# YTM32B1HA0 register map
Vendor: YTMicro; File version: 1.0
CPU: little endian, MPU, FPU, 2 interrupt priority bits
Registers are 32-bit, read-write, reset 0x0 unless marked. A register's access mark holds for its fields unless they carry their own. Offsets are from the block's base; [hi:lo] are bit positions; {n}, {i} and the like mark numbered series; 'fields as' and 'values as' point back to an identical list.

## ENET (part 10 of 10) — Ethernet Quality-of-Service
Base 0x401E4000; register names take the prefix ENET_
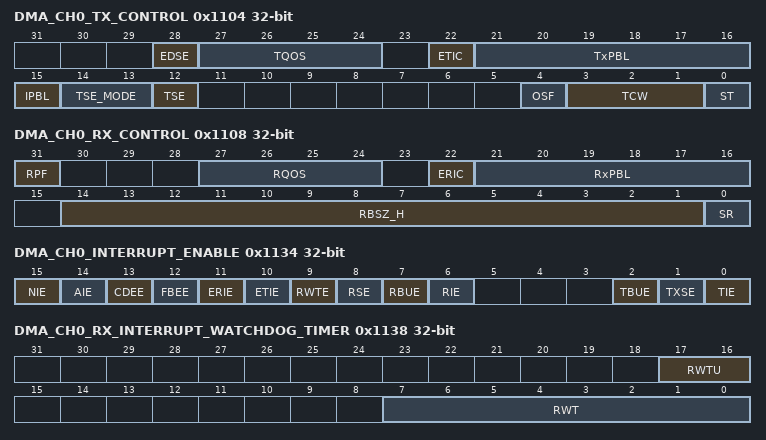
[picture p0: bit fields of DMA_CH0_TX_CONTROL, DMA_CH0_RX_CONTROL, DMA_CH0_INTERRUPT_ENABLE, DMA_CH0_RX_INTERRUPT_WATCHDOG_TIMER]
0x1104 DMA_CH0_TX_CONTROL — The DMA Channel n Transmit Control register controls the Tx features such as PBL, TCP segmentation, and Tx Channel weights.
  [28] EDSE — When this bit is set, the corresponding channel uses Enhanced Descriptors that are 32 Bytes for both Normal and Context Descriptors. When reset, the corresponding channel uses the descriptors that are 16 Bytes.
    0=Enhanced Descriptor is disabled; 1=Enhanced Descriptor is disabled
  [27:24] TQOS — This field is used to drive arqos_m_o[3:0] or awqos_m_o[3:0] output signals for all transactions of DMA Tx Channel n.
  [22] ETIC — When this bit is set, Early Transmit Interrupt (ETI) status is set after completion of transfer of data from buffers of a transmit descriptor in which IOC bit (TDES2[31]) is set. When this bit is reset, ETI is set only after a complete packet is transferred to the MTL TX FIFO memory.
    0=Early Transmit Interrupt is disabled; 1=Early Transmit Interrupt is enabled
  [21:16] TxPBL — These bits indicate the maximum number of beats to be transferred in one DMA block data transfer. The DMA always attempts max burst as specified in PBL each time it starts a burst transfer on the application bus. You can program PBL with any of the following values: 1, 2, 4, 8, 16, or 32. Any other value results in undefined behavior. To transfer more than 32 beats, perform the following steps: 1. Set the 8xPBL mode in DMA_CH0_Control register. 2. Set the TxPBL. Note: The maximum value of TxPBL must be less than or equal to half the Tx Queue size (TQS field of MTL_TxQ[n]_Operation_Mode register) in terms of beats. This is required so that the Tx Queue has space to store at least another Tx PBL worth of data while the MTL Tx Queue Controller is transferring data to MAC. For example, in 64-bit data width configurations the total locations in Tx Queue of size 512 bytes is 64, TxPBL and 8xPBL needs to be programmed to less than or equal to 32.
  [15] IPBL — When this bit is set, the DMA does not check for PBL number of locations in the MTL before initiating a transfer. If space is not available, the MTL may use handshaking to slow the DMA. Note: This bit/mode must not be used when multiple Transmit DMA Channels are enabled as it may block other Transmit and Receive DMA Channels from accessing the Read Data Channel of AXI bus until space is available in Transmit Queue for current transfer.
    0=Ignore PBL Requirement is disabled; 1=Ignore PBL Requirement is enabled
  [14:13] TSE_MODE
    0=TSO/USO (segmentation functionality is enabled). In this mode, the setting of TSE bit enables the TSO/USO segmentation.; 1=UFO with Checksum (UDP Fragmentation over IPv4 with Checksum). In this mode, the setting of TSE bit enables the UDP fragmentation functionality with Checksum for all the UDP packets.; 2=UFO without Checksum (UDP Fragmentation over IPv4 with Checksum). In this mode, the setting of TSE bit enables the UDP fragmentation functionality without Checksum for all the UDP packets.
  [12] TSE — When this bit is set, the DMA performs the TCP segmentation or UDP Segmentation/Fragmentation for packets in this channel. The TCP segmentation or UDP packet's segmentation/Fragmentation is done only for those packets for which the TSE bit (TDES0[19]) is set in the Tx Normal descriptor.When this bit is set, the TxPBL value must be greater than 4.
    0=TCP Segmentation is disabled; 1=TCP Segmentation is enabled
  [4] OSF — When this bit is set, it instructs the DMA to process the second packet of the Transmit data even before the status for the first packet is obtained.
    0=Operate on Second Packet disabled; 1=Operate on Second Packet enabled
  [3:1] TCW — This field indicates the weight assigned to the corresponding Transmit channel. When reset is complete, this field is set to 0 for all channels by default, resulting in equal weights to all channels.
  [0] ST — When this bit is set, transmission is placed in the Running state. The DMA checks the Transmit list at the current position for a packet to be transmitted. The DMA tries to acquire descriptor from either of the following positions: ■ The current position in the list This is the base address of the Transmit list set by the DMA_CH0_TxDesc_List_Address register. ■ The position at which the transmission was previously stopped If the DMA does not own the current descriptor, the transmission enters the Suspended state and the TBU bit of the DMA_CH0_Status register is set. The Start Transmission command is effective only when the transmission is stopped. If the command is issued before setting the DMA_CH0_TxDesc_List_Address register, the DMA behavior is unpredictable. When this bit is reset, the transmission process is placed in the Stopped state after completing the transmission of the current packet. The Next Descriptor position in the Transmit list is saved, and it becomes the current position when the transmission is restarted. To change the list address, you need to program DMA_CH0_TxDesc_List_Address register with a new value when this bit is reset. The new value is considered when this bit is set again. The stop transmission command is effective only when the transmission of the current packet is complete or the transmission is in the Suspended state.
    0=Stop Transmission Command; 1=Start Transmission Command
0x1108 DMA_CH0_RX_CONTROL — The DMA Channeli Receive Control register controls the Rx features such as PBL, buffer size, and extended status.
  [31] RPF — When this bit is set to 1, then DWC_ether_qos automatically flushes the packet from the Rx Queues destined to this DMA Rx Channel, when it is stopped. When this bit remains set and the DMA is re-started by the software driver, the packets residing in the Rx Queues that were received when this RxDMA was stopped, get flushed out. The packets that are received by the MAC after the RxDMA is re-started are routed to the RxDMA. The flushing happens on the Read side of the Rx Queue. When this bit is set to 0, the DWC_ether_qos not flush the packet in the Rx Queue destined to this RxDMA Channel when it is STOP state. This may in turn cause head-of-line blocking in the corresponding RxQueue.
    0=Rx Packet Flush is disabled; 1=Rx Packet Flush is enabled
  [27:24] RQOS — This field is used to drive arqos_m_o[3:0] or awqos_m_o[3:0] output signals for all transactions of DMA Rx Channel n.
  [22] ERIC — When this bit is set, Early Receive Interrupt (ERI) status is set after completion of every burst transfer of data from the Rx DMA to the buffer. When this bit is reset, ERI is set only after a complete buffer is filled up by the RxDMA.
    0=Early Receive Interrupt is disabled; 1=Early Receive Interrupt is disabled
  [21:16] RxPBL — These bits indicate the maximum number of beats to be transferred in one DMA block data transfer. The DMA always attempts max burst as specified in PBL each time it starts a burst transfer on the application bus. You can program PBL with any of the following values: 1, 2, 4, 8, 16, or 32. Any other value results in undefined behavior. To transfer more than 32 beats, perform the following steps: 1. Set the 8xPBL mode in the DMA_CH0_Control register. 2. Set the RxPBL. Note: The maximum value of RxPBL must be less than or equal to half the Rx Queue size (RQS field of MTL_RxQ[n]_Operation_Mode register) in terms of beats. This is required so that the Rx Queue has space to store at least another Rx PBL worth of data while the Rx DMA is transferring a block of data. For example, in 64-bit data width configurations the total locations in Rx Queue of size 512 bytes is 64, so RxPBL and 8xPBL needs to be programmed to less than or equal to 32.
  [14:1] RBSZ_H — RBSZ[13:0] is split into two fields higher RBSZ_13_y and lower RBSZ_x_0. The RBSZ[13:0] field indicates the size of the Rx buffers specified in bytes. The maximum buffer size is limited to 16K bytes. The buffer size is applicable to payload buffers when split headers are enabled. Note: The buffer size must be a multiple of 4, 8, or 16 depending on the data bus widths (32-bit, 64-bit, or 128-bit respectively). This is required even if the value of buffer address pointer is not aligned to data bus width. Hence the lower RBSZ_x_0 bits are read-only and the value is considered as all-zero. Thus the RBSZ_13_y indicates the buffer size in terms of locations (with the width same as bus-width).
  [0] SR — When this bit is set, the DMA tries to acquire the descriptor from the Receive list and processes the incoming packets. The DMA tries to acquire descriptor from either of the following positions: ■ The current position in the list This is the address set by the DMA_CH0_RxDesc_List_Address register. ■ The position at which the Rx process was previously stopped If the DMA does not own the current descriptor, the reception is suspended and the RBU bit of the DMA_CH0_Status register is set. The Start Receive command is effective only when the reception is stopped. If the command is issued before setting the DMA_CH0_RxDesc_List_Address register, the DMA behavior is unpredictable. When this bit is reset, the Rx DMA operation is stopped after the transfer of the current packet. The next descriptor position in the Receive list is saved, and it becomes the current position after the Rx process is restarted. The Stop Receive command is effective only when the Rx process is in the Running (waiting for Rx packet) or Suspended state.
    0=Stop Receive; 1=Start Receive
0x1110 DMA_CH0_TXDESC_LIST_HADDRESS — The Channeli Tx Descriptor List HAddress register has the higher 8 or 16 bits of the start address of the Transmit descriptor list. You can write to this register only when the Tx DMA has stopped, that is, the ST bit is set to zero in DMA_CHi_Tx_Control register. When stopped, this register can be written with a new descriptor list address. When you set the ST bit to 1, the DMA takes the newly-programmed descriptor base address. If this register is not changed when the ST bit is set to 0, the DMA takes the descriptor address where it was stopped earlier. This register must be programmed with desired the higher address before programming the DMA_CHi_TxDesc_List_Address register.
  [7:0] TDESHA — This field contains the most-significant 8 or 16 bits of the 40- or 48-bit base address of the first descriptor in the Transmit descriptor list.
0x1114 DMA_CH0_TXDESC_LIST_ADDRESS — The Channeli Tx Descriptor List Address register points the DMA to the start of Transmit descriptor list. The descriptor lists reside in the physical memory space of the application and must be Word, Dword, or Lword-aligned (for 32-bit, 64-bit, or 128-bit data bus). The DMA internally converts it to bus width aligned address by making the corresponding LSB to low. You can write to this register only when the Tx DMA has stopped, that is, the ST bit is set to zero in DMA_CH0_Tx_Control register. When stopped, this register can be written with a new descriptor list address. When you set the ST bit to 1, the DMA takes the newly-programmed descriptor base address. If this register is not changed when the ST bit is set to 0, the DMA takes the descriptor address where it was stopped earlier.
  [31:3] TDESLA — This field contains the base address of the first descriptor in the Transmit descriptor list. The DMA ignores the LSB bits (1:0, 2:0, or 3:0) for 32-bit, 64-bit, or 128-bit bus width and internally takes these bits as all-zero. Therefore, these LSB bits are read-only (RO). The width of this field depends on the configuration: ■ 31:2 for 32-bit configuration ■ 31:3 for 64-bit configuration ■ 31:4 for 128-bit configuration
0x1118 DMA_CH0_RXDESC_LIST_HADDRESS — The Channeli Rx Descriptor List HAddress register has the higher 8 or 16 bits of the start address of the Receive descriptor list. Writing to this register is permitted only when reception is stopped. When stopped, this register must be written to before the receive Start command is given. You can write to this register only when Rx DMA has stopped, that is, SR bit is set to zero in the DMA_CHi_RxDesc_List_Address register When you set the SR bit to 1, the DMA takes the newly programmed descriptor base address.
  [7:0] RDESHA — This field contains the most-significant 8 or 16 bits of the 40-bit or 48-bit base address of the first descriptor in the Rx Descriptor list.
0x111C DMA_CH0_RXDESC_LIST_ADDRESS — The Channeli Rx Descriptor List Address register points the DMA to the start of Receive descriptor list. This register points to the start of the Receive Descriptor List. The descriptor lists reside in the physical memory space of the application and must be Word, Dword, or Lword-aligned (for 32-bit, 64-bit, or 128-bit data bus). The DMA internally converts it to bus width aligned address by making the corre- sponding LS bits low. Writing to this register is permitted only when reception is stopped. When stopped, this register must be written to before the receive Start command is given. You can write to this register only when Rx DMA has stopped, that is, SR bit is set to zero in DMA_CH0_Rx_Control register. When stopped, this register can be written with a new descriptor list address. When you set the SR bit to 1, the DMA takes the newly programmed descriptor base address.
  [31:3] RDESLA — This field contains the base address of the first descriptor in the Receive descriptor list. The DMA ignores the LSB bits (1:0, 2:0, or 3:0) for 32-bit, 64-bit, or 128-bit bus width and internally takes these bits as all-zero. Therefore, these LSB bits are read-only (RO). The width of this field depends on the configuration: ■ 31:2 for 32-bit configuration ■ 31:3 for 64-bit configuration ■ 31:4 for 128-bit configuration
0x1120 DMA_CH0_TXDESC_TAIL_POINTER — The Channeli Tx Descriptor Tail Pointer register points to an offset from the base and indicates the location of the last valid descriptor.
  [31:3] TDTP — This field contains the tail pointer for the Tx descriptor ring. The software writes the tail pointer to add more descriptors to the Tx channel. The hardware tries to transmit all packets referenced by the descriptors between the head and the tail pointer registers. The width of this field depends on the configuration: ■ 31:2 for 32-bit configuration ■ 31:3 for 64-bit configuration ■ 31:4 for 128-bit configuration
0x1128 DMA_CH0_RXDESC_TAIL_POINTER — The Channel n Rx Descriptor Tail Pointer Points to an offset from the base and indicates the location of the last valid descriptor.
  [31:3] RDTP — This field contains the tail pointer for the Rx descriptor ring. The software writes the tail pointer to add more descriptors to the Rx channel. The hardware tries to receive all packets referenced by the descriptors between the head and the tail pointer registers. The width of this field depends on the configuration: ■ 31:2 for 32-bit configuration ■ 31:3 for 64-bit configuration ■ 31:4 for 128-bit configuration
0x112C DMA_CH0_TXDESC_RING_LENGTH — The Tx Descriptor Ring Length register contains the length of the Transmit descriptor ring.
  [9:0] TDRL — This field sets the maximum number of Tx descriptors in the circular descriptor ring. The maximum number of descriptors is limited to 1K descriptors. Synopsys recommends a minimum ring descriptor length of 4. For example, You can program any value up to 0x3FF in this field. This field is 10 bits wide, if you program 0x3FF, you can have 1024 descriptors. If you want to have 10 descriptors, program it to a value of 0x9.
0x1130 DMA_CH0_RXDESC_RING_LENGTH — The Channeli Rx Descriptor Ring Length register contains the length of the Receive descriptor circular ring.
  [9:0] RDRL — This field sets the maximum number of Rx descriptors in the circular descriptor ring. The maximum number of descriptors is limited to 1K descriptors. Synopsys recommends a minimum ring descriptor length of 4. For example, You can program any value up to 0x3FF in this field. This field is 10 bits wide, if you program 0x3FF, you can have 1024 descriptors. If you want to have 10 descriptors, program it to a value of 0x9.
0x1134 DMA_CH0_INTERRUPT_ENABLE — The Channel n Interrupt Enable register enables the interrupts reported by the Status register.
  [15] NIE — When this bit is set, the normal interrupt summary is enabled. This bit enables the following interrupts in the DMA_CH0_Status register: ■ Bit 0: Transmit Interrupt ■ Bit 2: Transmit Buffer Unavailable ■ Bit 6: Receive Interrupt ■ Bit 11: Early Receive Interrupt When this bit is reset, the normal interrupt summary is disabled.
    0=Normal Interrupt Summary is disabled; 1=Normal Interrupt Summary is enabled
  [14] AIE — When this bit is set, the abnormal interrupt summary is enabled. This bit enables the following interrupts in the DMA_CH0_Status register: ■ Bit 1: Transmit Process Stopped ■ Bit 7: Rx Buffer Unavailable ■ Bit 8: Receive Process Stopped ■ Bit 9: Receive Watchdog Timeout ■ Bit 10: Early Transmit Interrupt ■ Bit 12: Fatal Bus Error ■ Bit 13: Context Descriptor Error When this bit is reset, the abnormal interrupt summary is disabled.
    0=Abnormal Interrupt Summary is disabled; 1=Abnormal Interrupt Summary is enabled
  [13] CDEE — When this bit is set along with the AIE bit, the Descriptor error interrupt is enabled. When this bit is reset, the Descriptor error interrupt is disabled.
    0=Context Descriptor Error interrupt is disabled; 1=Context Descriptor Error interrupt is enabled
  [12] FBEE — When this bit is set along with the AIE bit, the Fatal Bus error interrupt is enabled. When this bit is reset, the Fatal Bus Error error interrupt is disabled.
    0=Fatal Bus Error interrupt is disabled; 1=Fatal Bus Error interrupt is enabled
  [11] ERIE — When this bit is set along with the NIE bit, the Early Receive interrupt is enabled. When this bit is reset, the Early Receive interrupt is disabled.
    0=Early Receive interrupt is disabled; 1=Early Receive interrupt is enabled
  [10] ETIE — When this bit is set along with the AIE bit, the Early Transmit interrupt is enabled. When this bit is reset, the Early Transmit interrupt is disabled.
    0=Early Transmit interrupt is disabled; 1=Early Transmit interrupt is enabled
  [9] RWTE — When this bit is set along with the AIE bit, the Receive Watchdog Timeout interrupt is enabled. When this bit is reset, the Receive Watchdog Timeout interrupt is disabled.
    0=Receive Watchdog Timeout interrupt is disabled; 1=Receive Watchdog Timeout interrupt is enabled
  [8] RSE — When this bit is set along with the AIE bit, the Receive Stopped interrupt is enabled. When this bit is reset, the Receive Stopped interrupt is disabled.
    0=Receive Stopped interrupt is disabled; 1=Receive Stopped interrupt is enabled
  [7] RBUE — When this bit is set along with the AIE bit, the Receive Buffer Unavailable interrupt is enabled. When this bit is reset, the Receive Buffer Unavailable interrupt is disabled.
    0=Receive Buffer Unavailable interrupt is disabled; 1=Receive Buffer Unavailable interrupt is enabled
  [6] RIE — When this bit is set along with the NIE bit, the Receive interrupt is enabled. When this bit is reset, the Receive interrupt is disabled.
    0=Receive interrupt is disabled; 1=Receive interrupt is enabled
  [2] TBUE — When this bit is set along with the NIE bit, the Transmit Buffer Unavailable interrupt is enabled. When this bit is reset, the Transmit Buffer Unavailable interrupt is disabled.
    0=Transmit Buffer Unavailable interrupt is disabled; 1=Transmit Buffer Unavailable interrupt is enabled
  [1] TXSE — When this bit is set along with the AIE bit, the Transmission Stopped interrupt is enabled. When this bit is reset, the Transmission Stopped interrupt is disabled.
    0=Transmit Stopped interrupt is disabled; 1=Transmit Stopped interrupt is enabled
  [0] TIE — When this bit is set along with the NIE bit, the Transmit interrupt is enabled. When this bit is reset, the Transmit interrupt is disabled.
    0=Transmit interrupt is disabled; 1=Transmit interrupt is enabled
0x1138 DMA_CH0_RX_INTERRUPT_WATCHDOG_TIMER — The Receive Interrupt Watchdog Timer register indicates the watchdog timeout for Receive Interrupt (RI) from the DMA. When this register is written with a non-zero value, it enables the watchdog timer for the RI bit of the DMA_CHn_Status register.
  [17:16] RWTU — This fields indicates the number of system clock cycles corresponding to one unit in RWT field. ■ 2'b00: 256 ■ 2'b01: 512 ■ 2'b10: 1024 ■ 2'b11: 2048 For example, when RWT=2 and RWTU=1, the watchdog timer is set for 2*512=1024 system clock cycles.
  [7:0] RWT — This field indicates the number of system clock cycles, multiplied by factor indicated in RWTU field, for which the watchdog timer is set. The watchdog timer is triggered with the programmed value after the Rx DMA completes the transfer of a packet for which the RI bit is not set in the DMA_CH(#i)_Status register, because of the setting of Interrupt Enable bit in the corresponding descriptor RDES3[30]. When the watchdog timer runs out, the RI bit is set and the timer is stopped. The watchdog timer is reset when the RI bit is set high because of automatic setting of RI as per the Interrupt Enable bit RDES3[30] of any received packet.
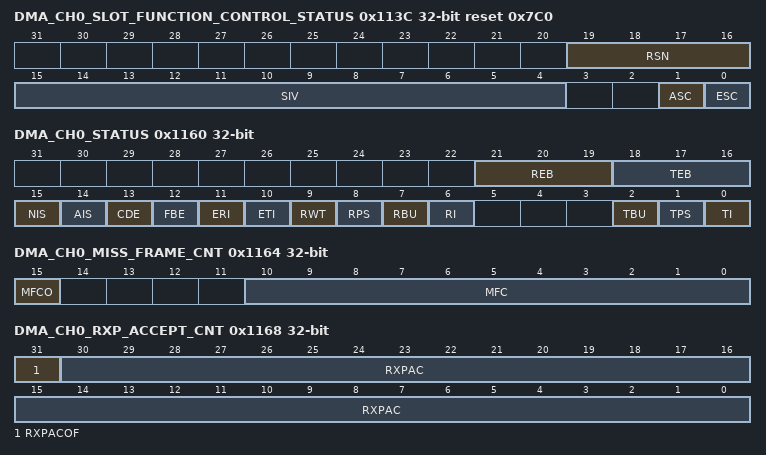
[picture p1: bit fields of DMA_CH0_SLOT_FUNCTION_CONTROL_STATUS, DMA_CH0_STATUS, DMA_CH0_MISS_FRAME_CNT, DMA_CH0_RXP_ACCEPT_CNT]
0x113C DMA_CH0_SLOT_FUNCTION_CONTROL_STATUS reset 0x7C0 — The Slot Function Control and Status register contains the control bits for slot function and the status for Transmit path.
  [19:16] RSN ro — This field gives the current value of the reference slot number in the DMA. It is used for slot comparison.
  [15:4] SIV — This field controls the period of the slot interval in which the TxDMA fetches the scheduled packets. A value of 0 specifies the slot interval of 1 us while the maximum value 4095 specifies the slot interval of 4096us. The default/reset value is 0x07C which corresponds to slot interval of 125us
  [1] ASC — When set, this bit enables the DMA to fetch the data from the buffer when the slot number (SLOTNUM) programmed in the Tx descriptor is ■ equal to the reference slot number given in the RSN field or ■ ahead of the reference slot number by up to two slots This bit is applicable only when the ESC bit is set. Values: ■ 0x0 (DISABLE): Advance Slot Check is disabled ■ 0x1 (ENABLE): Advance Slot Check is enabled
  [0] ESC — When set, this bit enables the checking of the slot numbers programmed in the Tx descriptor with the current reference given in the RSN field. The DMA fetches the data from the corresponding buffer only when the slot number is ■ equal to the reference slot number or ■ ahead of the reference slot number by one slot When reset, this bit disables the checking of the slot numbers. The DMA fetches the data immediately after the descriptor is processed. Note: The UFO (UDP Fragmentation over IPv4)/TSO/USO should not be enabled along with TBS/AVB Slot number check. The UFO/TSO/USO involves multiple packets/segments/fragments transmission for single packet received from application and the slot number check are applicable for fetching of only first segment/fragment. As a result it might be difficult for software to specify slot number for subsequent packets.
0x1144 DMA_CH0_CURRENT_APP_TXDESC ro — The Channeli Current Application Transmit Descriptor register points to the current Transmit descriptor read by the DMA.
  [31:0] CURTDESAPTR rw — The DMA updates this pointer during Tx operation. This pointer is cleared on reset.
0x114C DMA_CH0_CURRENT_APP_RXDESC ro — The Channel n Current Application Receive Descriptor register points to the current Receive descriptor read by the DMA.
  [31:0] CURRDESAPTR rw — The DMA updates this pointer during Rx operation. This pointer is cleared on reset.
0x1150 DMA_CH0_CURRENT_APP_TXBUFFER_H ro — The Channeli Current Application Transmit Buffer Address High register has the higher 8 or 16 bits of the current address of the Transmit buffer address read by the DMA.
  [7:0] CURTBUFAPTRH rw — The DMA updates this pointer during Tx operation. This pointer is cleared on reset.
0x1154 DMA_CH0_CURRENT_APP_TXBUFFER ro — The Channeli Current Application Transmit Buffer Address register points to the current Tx buffer address read by the DMA.
  [31:0] CURTBUFAPTR rw — The DMA updates this pointer during Tx operation. This pointer is cleared on reset.
0x1158 DMA_CH0_Current_App_RxBuffer_H ro — The Channel n Current Application Receive Buffer Address High register has the higher 8 or 16 bits of the current address of the Receive buffer address read by the DMA.
  [7:0] CURRBUFAPTRH rw — The DMA updates this pointer during Rx operation. This pointer is cleared on reset.
0x115C DMA_CH0_CURRENT_APP_RXBUFFER ro — The Channel n Current Application Receive Buffer Address register points to the current Rx buffer address read by the DMA.
  [31:0] CURRBUFAPTR rw — The DMA updates this pointer during Rx operation. This pointer is cleared on reset.
0x1160 DMA_CH0_STATUS ro — The software driver (application) reads the Status register during interrupt service routine or polling to determine the status of the DMA. Note: The number of DMA_CH[n]_Status register in the configuration is the higher of number of Rx DMA Channels and Tx DMA Channels.
  [21:19] REB rw — This field indicates the type of error that caused a Bus Error. For example, error response on the AHB or AXI interface. ■ Bit 21 ❑ 1'b1: Error during data transfer by Rx DMA ❑ 1'b0: No Error during data transfer by Rx DMA ■ Bit 20 ❑ 1'b1: Error during descriptor access ❑ 1'b0: Error during data buffer access ■ Bit 19 ❑ 1'b1: Error during read transfer ❑ 1'b0: Error during write transfer This field is valid only when the FBE bit is set. This field does not generate an interrupt.
  [18:16] TEB rw — This field indicates the type of error that caused a Bus Error. For example, error response on the AHB or AXI interface. ■ Bit 18 ❑ 1'b1: Error during data transfer by Tx DMA ❑ 1'b0: No Error during data transfer by Tx DMA ■ Bit 17 ❑ 1'b1: Error during descriptor access ❑ 1'b0: Error during data buffer access ■ Bit 16 ❑ 1'b1: Error during read transfer ❑ 1'b0: Error during write transfer This field is valid only when the FBE bit is set. This field does not generate an interrupt.
  [15] NIS rw — Normal Interrupt Summary bit value is the logical OR of the following bits when the corresponding interrupt bits are enabled in the DMA_CH0_Interrupt_Enable register: ■ Bit 0: Transmit Interrupt ■ Bit 2: Transmit Buffer Unavailable ■ Bit 6: Receive Interrupt ■ Bit 11: Early Receive Interrupt Only unmasked bits (interrupts for which interrupt enable is set in DMA_CH0_Interrupt_Enable register) affect the Normal Interrupt Summary bit. This is a sticky bit. You must clear this bit (by writing 1 to this bit) each time a corresponding bit which causes NIS to be set is cleared. Access restriction applies. Self-set to 1 on internal event. Setting 1 clears. Setting 0 has no effect.
  [14] AIS rw — Abnormal Interrupt Summary bit value is the logical OR of the following when the corresponding interrupt bits are enabled in the DMA_CH0_Interrupt_Enable register: ■ Bit 1: Transmit Process Stopped ■ Bit 7: Receive Buffer Unavailable ■ Bit 8: Receive Process Stopped ■ Bit 10: Early Transmit Interrupt ■ Bit 12: Fatal Bus Error ■ Bit 13: Context Descriptor Error Only unmasked bits affect the Abnormal Interrupt Summary bit. This is a sticky bit. You must clear this bit (by writing 1 to this bit) each time a corresponding bit, which causes AIS to be set, is cleared. Access restriction applies. Self-set to 1 on internal event. Setting 1 clears. Setting 0 has no effect.
    0=Abnormal Interrupt Summary status not detected; 1=Abnormal Interrupt Summary status detected
  [13] CDE rw — This bit indicates that the DMA Tx/Rx engine received a descriptor error, which indicates invalid context in the middle of packet flow ( intermediate descriptor) or all one's descriptor in Tx case and on Rx side it indicates DMA has read a descriptor with either of the buffer address as ones which is considered to be invalid. Access restriction applies. Self-set to 1 on internal event. Setting 1 clears. Setting 0 has no effect.
    0=Context Descriptor Error status not detected; 1=Context Descriptor Error status detected
  [12] FBE rw — This bit indicates that a bus error occurred (as described in the EB field). When this bit is set, the corresponding DMA channel engine disables all bus accesses. Access restriction applies. Self-set to 1 on internal event. Setting 1 clears. Setting 0 has no effect.
    0=Fatal Bus Error status not detected; 1=Fatal Bus Error status detected
  [11] ERI rw — This bit when set indicates that the RxDMA has completed the transfer of packet data to the memory. In configs supporting ERIC, When ERIC=0, this bit is set only after the Rx DMA has filled up a complete receive buffer with packet data. When ERIC=1, this bit is set after every burst transfer of data from the Rx DMA to the buffer. The setting of RI bit automatically clears this bit. Access restriction applies. Self-set to 1 on internal event. Setting 1 clears. Setting 0 has no effect.
    0=Early Receive Interrupt status not detected; 1=Early Receive Interrupt status detected
  [10] ETI rw — This bit when set indicates that the TxDMA has completed the transfer of packet data to the MTL TXFIFO memory. In configs supporting ERIC: When ETIC=0, this bit is set only after the Tx DMA has transferred a complete packet to MTL. When ETIC=1, this bit is set after completion of (partial) packet data transfer from buffers in the Transmit descriptor in which IOC=1. Access restriction applies. Self-set to 1 on internal event. Setting 1 clears. Setting 0 has no effect.
    0=Early Transmit Interrupt status not detected; 1=Early Transmit Interrupt status detected
  [9] RWT rw — This bit is asserted when a packet with length greater than 2,048 bytes (10,240 bytes when Jumbo Packet mode is enabled) is received.
    0=Receive Watchdog Timeout status not detected; 1=Receive Watchdog Timeout status detected
  [8] RPS rw — This bit is asserted when the Rx process enters the Stopped state. Access restriction applies. Self-set to 1 on internal event. Setting 1 clears. Setting 0 has no effect.
    0=Receive Process Stopped status not detected; 1=Receive Process Stopped status detected
  [7] RBU rw — This bit indicates that the application owns the next descriptor in the Receive list, and the DMA cannot acquire it. The Rx process is suspended. To resume processing Rx descriptors, the application should change the ownership of the descriptor and issue a Receive Poll Demand command. If this command is not issued, the Rx process resumes when the next recognized incoming packet is received. In ring mode, the application should advance the Receive Descriptor Tail Pointer register of a channel. This bit is set only when the DMA owns the previous Rx descriptor. Access restriction applies. Self-set to 1 on internal event. Setting 1 clears. Setting 0 has no effect.
    0=Receive Buffer Unavailable status not detected; 1=Receive Buffer Unavailable status detected
  [6] RI rw — This bit indicates that the packet reception is complete. When packet reception is complete, Bit 31 of RDES3 is reset in the last descriptor, and the specific packet status information is updated in the descriptor. The reception remains in the Running state. Access restriction applies. Self-set to 1 on internal event. Setting 1 clears. Setting 0 has no effect.
    0=Receive Interrupt status not detected; 1=Receive Interrupt status detected
  [2] TBU rw — This bit indicates that the application owns the next descriptor in the Transmit list, and the DMA cannot acquire it. Transmission is suspended. The TPS0 field of the DMA_Debug_Status0 register explains the Transmit Process state transitions. To resume processing the Transmit descriptors, the application should do the following: 1. Change the ownership of the descriptor by setting Bit 31 of TDES3. 2. Issue a Transmit Poll Demand command. For ring mode, the application should advance the Transmit Descriptor Tail Pointer register of a channel. Access restriction applies. Self-set to 1 on internal event. Setting 1 clears. Setting 0 has no effect.
    0=Transmit Buffer Unavailable status not detected; 1=Transmit Buffer Unavailable status detected
  [1] TPS rw — This bit is set when the transmission is stopped. Access restriction applies. Self-set to 1 on internal event. Setting 1 clears. Setting 0 has no effect.
    0=Transmit Process Stopped status not detected; 1=Transmit Process Stopped status detected
  [0] TI rw — This bit indicates that the packet transmission is complete. When transmission is complete, Bit 31 of TDES3 is reset in the last descriptor, and the specific packet status information is updated in the descriptor. Access restriction applies. Self-set to 1 on internal event. Setting 1 clears. Setting 0 has no effect.
    0=Transmit Interrupt status not detected; 1=Transmit Interrupt status detected
0x1164 DMA_CH0_MISS_FRAME_CNT ro — This register has the number of packet counter that got dropped by the DMA either due to Bus Error or due to programming RPF field in DMA_CH${i}_Rx_Control register.
  [15] MFCO rw — When this bit is set then the MFC counter does not get incremented further. The bit gets cleared when this register is read. Access restriction applies. Clears on read. Self-set to 1 on internal event.
    0=Miss Frame Counter overflow not occurred; 1=Miss Frame Counter overflow occurred
  [10:0] MFC rw — This counter indicates the number of packet counters that are dropped by the DMA either because of bus error or because of programing RPF field in DMA_CH${i}_Rx_Control register. The counter gets cleared when this register is read. Access restriction applies. Clears on read. Self-set to 1 on internal event.
0x1168 DMA_CH0_RXP_ACCEPT_CNT ro — The DMA_CHn_RXP_Accept_Cnt registers provides the count of the number of frames accepted by Rx Parser.
  [31] RXPACOF rw — When set, this bit indicates that the RXPAC Counter field crossed the maximum limit. Access restriction applies. Clears on read. Self-set to 1 on internal event.
    0=Rx Parser Accept Counter overflow not occurred; 1=Rx Parser Accept Counter overflow occurred
  [30:0] RXPAC rw — This 31-bit counter is implemented whenever a Rx Parser Accept a packet due to AF =1. The counter is cleared when the register is read.
0x116C DMA_CH0_RX_ERI_CNT ro — The DMA_CHn_RX_ERI_Cnt registers provides the count of the number of times ERI was asserted.
  [11:0] ECNT rw — When ERIC bit of DMA_CHn_RX_Control register is set, this counter increments for burst transfer completed by the Rx DMA from the start of packet transfer. This counter will get reset at the start of new packet.
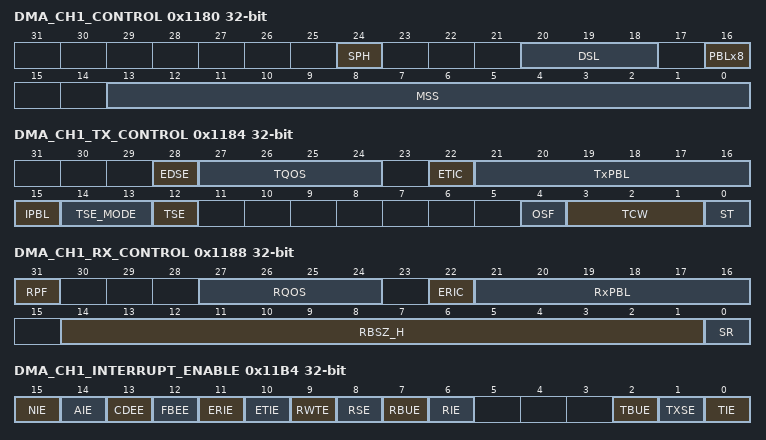
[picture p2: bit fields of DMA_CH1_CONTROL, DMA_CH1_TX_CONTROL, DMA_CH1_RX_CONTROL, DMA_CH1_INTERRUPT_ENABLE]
0x1180 DMA_CH1_CONTROL — The DMA Channel n Control register specifies the MSS value for segmentation, length to skip between two descriptors, and also the features such as header splitting and 8xPBL mode.
  [24] SPH — When this bit is set, the DMA splits the header and payload in the Receive path. The DMA writes the header to the Buffer Address1 of RDES0. The DMA writes the payload to the buffer to which the Buffer Address2 is pointing. The software must ensure that the header fits into the Receive buffers. If the header length exceeds the receive buffer size, the DMA does not split the header and payload. This bit is available only if Enable Split Header Structure option is selected.
    0=Split Headers feature is disabled; 1=Split Headers feature is enabled
  [20:18] DSL — This bit specifies the Word, Dword, or Lword number (depending on the 32-bit, 64-bit, or 128-bit bus) to skip between two unchained descriptors. The address skipping starts from the end of the current descriptor to the start of the next descriptor. When the DSL value is equal to zero, the DMA takes the descriptor table as contiguous.
  [16] PBLx8 — When this bit is set, the PBL value programmed in Bits[21:16] in DMA_CH0_Tx_Control and Bits[21:16] in DMA_CH0_Rx_Control is multiplied by eight times. Therefore, the DMA transfers the data in 8, 16, 32, 64, 128, and 256 beats depending on the PBL value.
    0=8xPBL mode is disabled; 1=8xPBL mode is enabled
  [13:0] MSS — This field specifies the maximum segment size that should be used while segmenting the packet. This field is valid only if the TSE bit of DMA_CH0_Tx_Control register is set. The value programmed in this field must be more than the configured Datawidth in bytes. It is recommended to use a MSS value of 64 bytes or more.
0x1184 DMA_CH1_TX_CONTROL — The DMA Channel n Transmit Control register controls the Tx features such as PBL, TCP segmentation, and Tx Channel weights.
  fields as DMA_CH0_TX_CONTROL
0x1188 DMA_CH1_RX_CONTROL — The DMA Channeli Receive Control register controls the Rx features such as PBL, buffer size, and extended status.
  fields as DMA_CH0_RX_CONTROL
0x1190 DMA_CH1_TXDESC_LIST_HADDRESS — The Channeli Tx Descriptor List HAddress register has the higher 8 or 16 bits of the start address of the Transmit descriptor list. You can write to this register only when the Tx DMA has stopped, that is, the ST bit is set to zero in DMA_CHi_Tx_Control register. When stopped, this register can be written with a new descriptor list address. When you set the ST bit to 1, the DMA takes the newly-programmed descriptor base address. If this register is not changed when the ST bit is set to 0, the DMA takes the descriptor address where it was stopped earlier. This register must be programmed with desired the higher address before programming the DMA_CHi_TxDesc_List_Address register.
  fields as DMA_CH0_TXDESC_LIST_HADDRESS
0x1194 DMA_CH1_TXDESC_LIST_ADDRESS — The Channeli Tx Descriptor List Address register points the DMA to the start of Transmit descriptor list. The descriptor lists reside in the physical memory space of the application and must be Word, Dword, or Lword-aligned (for 32-bit, 64-bit, or 128-bit data bus). The DMA internally converts it to bus width aligned address by making the corresponding LSB to low. You can write to this register only when the Tx DMA has stopped, that is, the ST bit is set to zero in DMA_CH0_Tx_Control register. When stopped, this register can be written with a new descriptor list address. When you set the ST bit to 1, the DMA takes the newly-programmed descriptor base address. If this register is not changed when the ST bit is set to 0, the DMA takes the descriptor address where it was stopped earlier.
  fields as DMA_CH0_TXDESC_LIST_ADDRESS
0x1198 DMA_CH1_RXDESC_LIST_HADDRESS — The Channeli Rx Descriptor List HAddress register has the higher 8 or 16 bits of the start address of the Receive descriptor list. Writing to this register is permitted only when reception is stopped. When stopped, this register must be written to before the receive Start command is given. You can write to this register only when Rx DMA has stopped, that is, SR bit is set to zero in the DMA_CHi_RxDesc_List_Address register When you set the SR bit to 1, the DMA takes the newly programmed descriptor base address.
  fields as DMA_CH0_RXDESC_LIST_HADDRESS
0x119C DMA_CH1_RXDESC_LIST_ADDRESS — The Channeli Rx Descriptor List Address register points the DMA to the start of Receive descriptor list. This register points to the start of the Receive Descriptor List. The descriptor lists reside in the physical memory space of the application and must be Word, Dword, or Lword-aligned (for 32-bit, 64-bit, or 128-bit data bus). The DMA internally converts it to bus width aligned address by making the corre- sponding LS bits low. Writing to this register is permitted only when reception is stopped. When stopped, this register must be written to before the receive Start command is given. You can write to this register only when Rx DMA has stopped, that is, SR bit is set to zero in DMA_CH0_Rx_Control register. When stopped, this register can be written with a new descriptor list address. When you set the SR bit to 1, the DMA takes the newly programmed descriptor base address.
  fields as DMA_CH0_RXDESC_LIST_ADDRESS
0x11A0 DMA_CH1_TXDESC_TAIL_POINTER — The Channeli Tx Descriptor Tail Pointer register points to an offset from the base and indicates the location of the last valid descriptor.
  fields as DMA_CH0_TXDESC_TAIL_POINTER
0x11A8 DMA_CH1_RXDESC_TAIL_POINTER — The Channel n Rx Descriptor Tail Pointer Points to an offset from the base and indicates the location of the last valid descriptor.
  fields as DMA_CH0_RXDESC_TAIL_POINTER
0x11AC DMA_CH1_TXDESC_RING_LENGTH — The Tx Descriptor Ring Length register contains the length of the Transmit descriptor ring.
  fields as DMA_CH0_TXDESC_RING_LENGTH
0x11B0 DMA_CH1_RXDESC_RING_LENGTH — The Channeli Rx Descriptor Ring Length register contains the length of the Receive descriptor circular ring.
  fields as DMA_CH0_RXDESC_RING_LENGTH
0x11B4 DMA_CH1_INTERRUPT_ENABLE — The Channel n Interrupt Enable register enables the interrupts reported by the Status register.
  fields as DMA_CH0_INTERRUPT_ENABLE
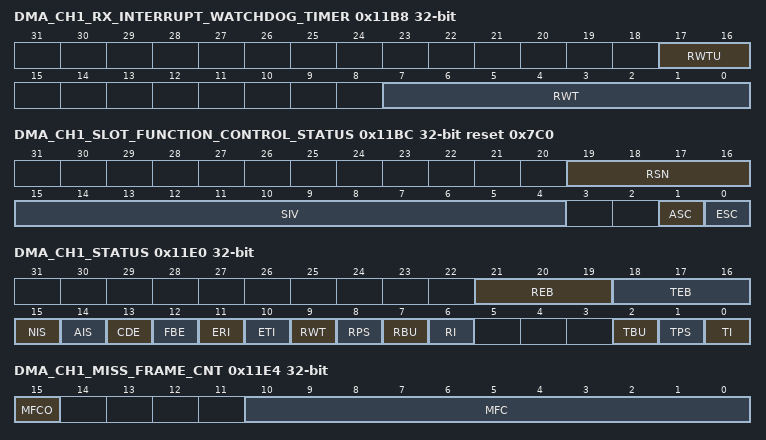
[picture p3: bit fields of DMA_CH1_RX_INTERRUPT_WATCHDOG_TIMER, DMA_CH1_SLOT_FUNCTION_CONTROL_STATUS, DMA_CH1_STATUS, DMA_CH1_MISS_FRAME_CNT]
0x11B8 DMA_CH1_RX_INTERRUPT_WATCHDOG_TIMER — The Receive Interrupt Watchdog Timer register indicates the watchdog timeout for Receive Interrupt (RI) from the DMA. When this register is written with a non-zero value, it enables the watchdog timer for the RI bit of the DMA_CHn_Status register.
  fields as DMA_CH0_RX_INTERRUPT_WATCHDOG_TIMER
0x11BC DMA_CH1_SLOT_FUNCTION_CONTROL_STATUS reset 0x7C0 — The Slot Function Control and Status register contains the control bits for slot function and the status for Transmit path.
  fields as DMA_CH0_SLOT_FUNCTION_CONTROL_STATUS
0x11C4 DMA_CH1_CURRENT_APP_TXDESC ro — The Channeli Current Application Transmit Descriptor register points to the current Transmit descriptor read by the DMA.
  fields as DMA_CH0_CURRENT_APP_TXDESC
0x11CC DMA_CH1_CURRENT_APP_RXDESC ro — The Channel n Current Application Receive Descriptor register points to the current Receive descriptor read by the DMA.
  fields as DMA_CH0_CURRENT_APP_RXDESC
0x11D0 DMA_CH1_CURRENT_APP_TXBUFFER_H ro — The Channeli Current Application Transmit Buffer Address High register has the higher 8 or 16 bits of the current address of the Transmit buffer address read by the DMA.
  fields as DMA_CH0_CURRENT_APP_TXBUFFER_H
0x11D4 DMA_CH1_CURRENT_APP_TXBUFFER ro — The Channeli Current Application Transmit Buffer Address register points to the current Tx buffer address read by the DMA.
  fields as DMA_CH0_CURRENT_APP_TXBUFFER
0x11D8 DMA_CH1_Current_App_RxBuffer_H ro — The Channel n Current Application Receive Buffer Address High register has the higher 8 or 16 bits of the current address of the Receive buffer address read by the DMA.
  fields as DMA_CH0_Current_App_RxBuffer_H
0x11DC DMA_CH1_CURRENT_APP_RXBUFFER ro — The Channel n Current Application Receive Buffer Address register points to the current Rx buffer address read by the DMA.
  fields as DMA_CH0_CURRENT_APP_RXBUFFER
0x11E0 DMA_CH1_STATUS ro — The software driver (application) reads the Status register during interrupt service routine or polling to determine the status of the DMA. Note: The number of DMA_CH[n]_Status register in the configuration is the higher of number of Rx DMA Channels and Tx DMA Channels.
  fields as DMA_CH0_STATUS
0x11E4 DMA_CH1_MISS_FRAME_CNT ro — This register has the number of packet counter that got dropped by the DMA either due to Bus Error or due to programming RPF field in DMA_CH${i}_Rx_Control register.
  fields as DMA_CH0_MISS_FRAME_CNT
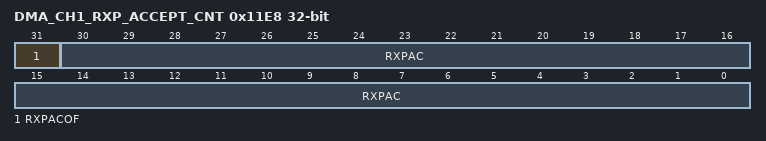
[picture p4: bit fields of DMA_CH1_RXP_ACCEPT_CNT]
0x11E8 DMA_CH1_RXP_ACCEPT_CNT ro — The DMA_CHn_RXP_Accept_Cnt registers provides the count of the number of frames accepted by Rx Parser.
  fields as DMA_CH0_RXP_ACCEPT_CNT
0x11EC DMA_CH1_RX_ERI_CNT ro — The DMA_CHn_RX_ERI_Cnt registers provides the count of the number of times ERI was asserted.
  fields as DMA_CH0_RX_ERI_CNT
